# TMS320F280049 register map
Vendor: Texas Instruments; Series: C2000 F28004x; File version: 0.2.0-generated
Registers are 16-bit, read-write, reset 0x0 unless marked. A register's access mark holds for its fields unless they carry their own. Offsets are from the block's base; [hi:lo] are bit positions.

## FSITXAREGS — FSI TX Registers
Base 0x0000CC00
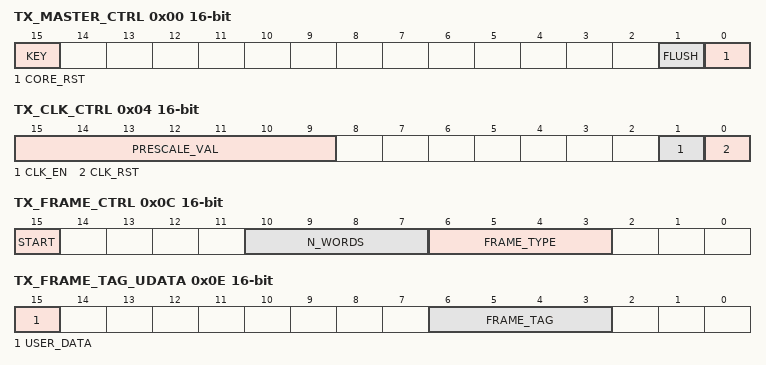
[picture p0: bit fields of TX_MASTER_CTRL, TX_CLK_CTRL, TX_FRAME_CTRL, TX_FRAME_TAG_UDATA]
0x00 TX_MASTER_CTRL — Transmit master control register
  [15] KEY — Write Key
  [1] FLUSH — Flush Operation Start
  [0] CORE_RST — Transmitter Main Core Reset
0x04 TX_CLK_CTRL — Transmit clock control register
  [15:9] PRESCALE_VAL — Prescale value
  [1] CLK_EN — Clock Divider Enable
  [0] CLK_RST — Soft Reset for the Clock Divider
0x08 TX_OPER_CTRL_LO — Transmit operation control register low
  [8] SEL_PLLCLK — Input Clock Select
  [7] PING_TO_MODE — Ping Counter Reset Mode Select
  [6] SW_CRC — CRC Source Select
  [7:5] START_MODE — Transmission Start Mode Select
  [2] SPI_MODE — SPI Mode Select
  [2:1] DATA_WIDTH — Transmit Data width
0x0A TX_OPER_CTRL_HI — Transmit operation control register high
  [6] ECC_SEL — ECC Data Width Select
  [5] FORCE_ERR — Error Frame Force
  [8:4] EXT_TRIG_SEL — External Trigger Select
0x0C TX_FRAME_CTRL — Transmit frame control register
  [15] START — Start Transmission
  [10:7] N_WORDS — Number of Words to be Transmitted
  [6:3] FRAME_TYPE — Transmit Frame Type
0x0E TX_FRAME_TAG_UDATA — Transmit frame tag and user data register
  [15] USER_DATA, [6:3] FRAME_TAG
0x10 TX_BUF_PTR_LOAD — Transmit buffer pointer control load register
  [6:3] BUF_PTR_LOAD — Buffer Pointer Force Load
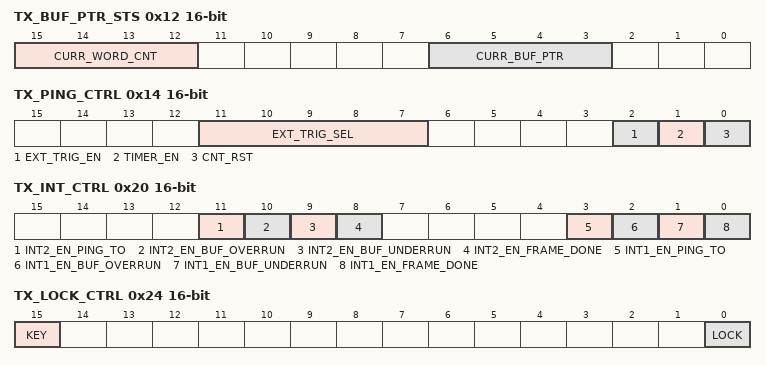
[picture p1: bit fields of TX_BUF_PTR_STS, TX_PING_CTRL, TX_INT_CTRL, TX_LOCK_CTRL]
0x12 TX_BUF_PTR_STS — Transmit buffer pointer control status register
  [15:12] CURR_WORD_CNT — Remaining Words in Buffer
  [6:3] CURR_BUF_PTR — Current Buffer Pointer Index
0x14 TX_PING_CTRL — Transmit ping control register
  [11:7] EXT_TRIG_SEL — External Trigger Select
  [2] EXT_TRIG_EN — External Trigger Enable
  [1] TIMER_EN — Ping Counter Enable
  [0] CNT_RST — Ping Counter Reset
0x16 TX_PING_TAG — Transmit ping tag register
  [6:3] TAG — Ping Frame Tag
0x18 TX_PING_TO_REF 32-bit — Transmit ping timeout counter reference
  [31] TO_REF — Ping Timer Reference
0x1C TX_PING_TO_CNT 32-bit — Transmit ping timeout current count
  [31] TO_CNT — Ping Timer Counter
0x20 TX_INT_CTRL — Transmit interrupt event control register
  [11] INT2_EN_PING_TO — Enable Ping Timer Interrupt to INT2
  [10] INT2_EN_BUF_OVERRUN — Enable Buffer Overrun Interrupt to INT2
  [9] INT2_EN_BUF_UNDERRUN — Enable Buffer Underrun Interrupt to INT2
  [8] INT2_EN_FRAME_DONE — Enable Frame Done Interrupt to INT2
  [3] INT1_EN_PING_TO — Enable Ping Timer Interrupt to INT1
  [2] INT1_EN_BUF_OVERRUN — Enable Buffer Overrun Interrupt to INT1
  [1] INT1_EN_BUF_UNDERRUN — Enable Buffer Underrun Interrupt to INT1
  [0] INT1_EN_FRAME_DONE — Enable Frame Done Interrupt to INT1
0x22 TX_DMA_CTRL — Transmit DMA event control register
  [0] DMA_EVT_EN — DMA Event Enable
0x24 TX_LOCK_CTRL — Transmit lock control register
  [15] KEY — Write Key
  [0] LOCK — Control Register Lock Enable
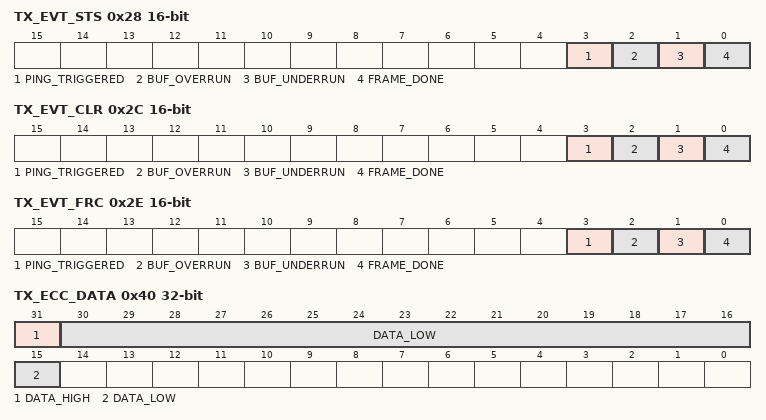
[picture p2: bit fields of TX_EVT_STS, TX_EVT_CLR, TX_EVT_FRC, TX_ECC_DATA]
0x28 TX_EVT_STS — Transmit event and error status flag register
  [3] PING_TRIGGERED — Ping Frame Triggered Flag
  [2] BUF_OVERRUN — Buffer Overrun Flag
  [1] BUF_UNDERRUN — Buffer Underrun Flag
  [0] FRAME_DONE — Frame Done Flag
0x2C TX_EVT_CLR — Transmit event and error clear register
  [3] PING_TRIGGERED — Ping Frame Triggered Flag Clear
  [2] BUF_OVERRUN — Buffer Overrun Flag Clear
  [1] BUF_UNDERRUN — Buffer Underrun Flag Clear
  [0] FRAME_DONE — Frame Done Flag Clear
0x2E TX_EVT_FRC — Transmit event and error flag force register
  [3] PING_TRIGGERED — Ping Frame Triggered Flag Force
  [2] BUF_OVERRUN — Buffer Overrun Flag Force
  [1] BUF_UNDERRUN — Buffer Underrun Flag Force
  [0] FRAME_DONE — Frame Done Flag Force
0x30 TX_USER_CRC — Transmit user-defined CRC register
  [14:7] USER_CRC — User-defined CRC
0x40 TX_ECC_DATA 32-bit — Transmit ECC data register
  [31] DATA_HIGH — ECC Data Upper 16 Bits
  [30:15] DATA_LOW — ECC Data Lower 16 Bits
0x44 TX_ECC_VAL — Transmit ECC value register
  [12:6] ECC_VAL — Computed ECC Value
0x80 TX_BUF_BASE — Base address for transmit buffer
  [15] BASE_ADDRESS — Transmit Data Buffer Base Address
